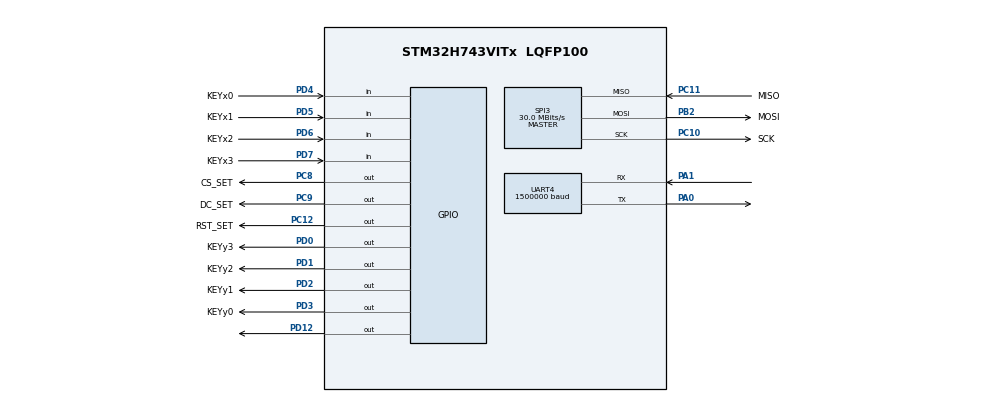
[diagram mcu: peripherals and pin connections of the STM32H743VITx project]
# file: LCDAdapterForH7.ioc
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Dma.Request0=UART4_RX
Dma.UART4_RX.0.Direction=DMA_PERIPH_TO_MEMORY
Dma.UART4_RX.0.EventEnable=DISABLE
Dma.UART4_RX.0.FIFOMode=DMA_FIFOMODE_DISABLE
Dma.UART4_RX.0.Instance=DMA1_Stream0
Dma.UART4_RX.0.MemDataAlignment=DMA_MDATAALIGN_WORD
Dma.UART4_RX.0.MemInc=DMA_MINC_ENABLE
Dma.UART4_RX.0.Mode=DMA_NORMAL
Dma.UART4_RX.0.PeriphDataAlignment=DMA_PDATAALIGN_WORD
Dma.UART4_RX.0.PeriphInc=DMA_PINC_DISABLE
Dma.UART4_RX.0.Polarity=HAL_DMAMUX_REQ_GEN_RISING
Dma.UART4_RX.0.Priority=DMA_PRIORITY_LOW
Dma.UART4_RX.0.RequestNumber=1
Dma.UART4_RX.0.SignalID=NONE
Dma.UART4_RX.0.SyncEnable=DISABLE
Dma.UART4_RX.0.SyncPolarity=HAL_DMAMUX_SYNC_NO_EVENT
Dma.UART4_RX.0.SyncRequestNumber=1
Dma.UART4_RX.0.SyncSignalID=NONE
Mcu.Family=STM32H7
Mcu.Name=STM32H743VITx
Mcu.Package=LQFP100
NVIC.DMA1_Stream0_IRQn=true\:0\:0\:false\:false\:true\:false\:true
NVIC.PriorityGroup=NVIC_PRIORITYGROUP_4
PA0.Mode=Asynchronous
PA0.Signal=UART4_TX
PA1.Mode=Asynchronous
PA1.Signal=UART4_RX
PA13\ (JTMS/SWDIO).Mode=JTAG_4_pins
PA13\ (JTMS/SWDIO).Signal=DEBUG_JTMS-SWDIO
PA14\ (JTCK/SWCLK).Mode=JTAG_4_pins
PA14\ (JTCK/SWCLK).Signal=DEBUG_JTCK-SWCLK
PA15\ (JTDI).Mode=JTAG_4_pins
PA15\ (JTDI).Signal=DEBUG_JTDI
PB2.GPIO_Label=MOSI
PB2.GPIO_Speed=GPIO_SPEED_FREQ_VERY_HIGH
PB2.Mode=Full_Duplex_Master
PB2.Signal=SPI3_MOSI
PB3\ (JTDO/TRACESWO).Mode=JTAG_4_pins
PB3\ (JTDO/TRACESWO).Signal=DEBUG_JTDO-SWO
PC10.GPIO_Label=SCK
PC10.GPIO_Speed=GPIO_SPEED_FREQ_VERY_HIGH
PC10.Mode=Full_Duplex_Master
PC10.Signal=SPI3_SCK
PC11.GPIO_Label=MISO
PC11.GPIO_Speed=GPIO_SPEED_FREQ_VERY_HIGH
PC11.Mode=Full_Duplex_Master
PC11.Signal=SPI3_MISO
PC12.GPIO_Label=RST_SET
PC12.GPIO_Speed=GPIO_SPEED_FREQ_VERY_HIGH
PC12.Signal=GPIO_Output
PC14-OSC32_IN\ (OSC32_IN).Mode=LSE-External-Oscillator
PC14-OSC32_IN\ (OSC32_IN).Signal=RCC_OSC32_IN
PC15-OSC32_OUT\ (OSC32_OUT).Mode=LSE-External-Oscillator
PC15-OSC32_OUT\ (OSC32_OUT).Signal=RCC_OSC32_OUT
PC8.GPIO_Label=CS_SET
PC8.GPIO_Speed=GPIO_SPEED_FREQ_VERY_HIGH
PC8.Signal=GPIO_Output
PC9.GPIO_Label=DC_SET
PC9.GPIO_Speed=GPIO_SPEED_FREQ_LOW
PC9.Signal=GPIO_Output
PD0.GPIO_Label=KEYy3
PD0.Signal=GPIO_Output
PD1.GPIO_Label=KEYy2
PD1.Signal=GPIO_Output
PD12.PinState=GPIO_PIN_SET
PD12.Signal=GPIO_Output
PD2.GPIO_Label=KEYy1
PD2.Signal=GPIO_Output
PD3.GPIO_Label=KEYy0
PD3.Signal=GPIO_Output
PD4.GPIO_Label=KEYx0
PD4.GPIO_PuPd=GPIO_PULLUP
PD4.Signal=GPIO_Input
PD5.GPIO_Label=KEYx1
PD5.GPIO_PuPd=GPIO_PULLUP
PD5.Signal=GPIO_Input
PD6.GPIO_Label=KEYx2
PD6.GPIO_PuPd=GPIO_PULLUP
PD6.Signal=GPIO_Input
PD7.GPIO_Label=KEYx3
PD7.GPIO_PuPd=GPIO_PULLUP
PD7.Signal=GPIO_Input
PH0-OSC_IN\ (PH0).Mode=HSE-External-Clock-Source
PH0-OSC_IN\ (PH0).Signal=RCC_OSC_IN
PH1-OSC_OUT\ (PH1).Mode=HSE-External-Clock-Source
PH1-OSC_OUT\ (PH1).Signal=RCC_OSC_OUT
ProjectManager.HeapSize=0x200
ProjectManager.StackSize=0x400
ProjectManager.TargetToolchain=STM32CubeIDE
RCC.ADCFreq_Value=129000000
RCC.APB1Freq_Value=120000000
RCC.APB2Freq_Value=120000000
RCC.APB3Freq_Value=120000000
RCC.APB4Freq_Value=120000000
RCC.CortexFreq_Value=480000000
RCC.D1PPRE=RCC_APB3_DIV2
RCC.D2PPRE1=RCC_APB1_DIV2
RCC.D2PPRE2=RCC_APB2_DIV2
RCC.D3PPRE=RCC_APB4_DIV2
RCC.DIVM1=4
RCC.DIVN1=60
RCC.HCLKFreq_Value=240000000
RCC.HPRE=RCC_HCLK_DIV2
RCC.PLL2FRACN=0
RCC.PLL3FRACN=0
RCC.PLLFRACN=0
RCC.SYSCLKFreq_VALUE=480000000
RCC.SYSCLKSource=RCC_SYSCLKSOURCE_PLLCLK
RCC.USBFreq_Value=480000000
SPI3.BaudRatePrescaler=SPI_BAUDRATEPRESCALER_16
SPI3.CLKPhase=SPI_PHASE_2EDGE
SPI3.CLKPolarity=SPI_POLARITY_HIGH
SPI3.CalculateBaudRate=30.0 MBits/s
SPI3.DataSize=SPI_DATASIZE_8BIT
SPI3.Direction=SPI_DIRECTION_2LINES
SPI3.Mode=SPI_MODE_MASTER
SPI3.NSSPMode=SPI_NSS_PULSE_DISABLE
SPI3.VirtualType=VM_MASTER
UART4.BaudRate=1500000
board=custom

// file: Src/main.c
/* USER CODE BEGIN Header */
/**
  ******************************************************************************
  * @file           : main.c
  * @brief          : Main program body
  ******************************************************************************
  * @attention
  *
  * <h2><center>&copy; Copyright (c) 2019 STMicroelectronics.
  * All rights reserved.</center></h2>
  *
  * This software component is licensed by ST under BSD 3-Clause license,
  * the "License"; You may not use this file except in compliance with the
  * License. You may obtain a copy of the License at:
  *                        opensource.org/licenses/BSD-3-Clause
  *
  ******************************************************************************
  */
/* USER CODE END Header */

#include <gui.h>
#include "main.h"
#include "dma.h"
#include "spi.h"
#include "usart.h"
#include "gpio.h"

/* USER CODE BEGIN Includes */
#include "KeyPad.h"
#include "MyMain.h"
/* USER CODE END Includes */

/* USER CODE BEGIN PV */
extern uint32_t ImgIn[38400];
/* USER CODE END PV */

void SystemClock_Config(void);

int main(void)
{

  /* MCU Configuration--------------------------------------------------------*/

  /* Reset of all peripherals, Initializes the Flash interface and the Systick. */
  HAL_Init();

  /* Configure the system clock */
  SystemClock_Config();

  /* Initialize all configured peripherals */
  MX_GPIO_Init();
  MX_DMA_Init();
  MX_SPI3_Init();
  MX_UART4_Init();
  /* USER CODE BEGIN 2 */
	Lcd_Init();
	HAL_UART_Receive_DMA(&huart4,ImgIn,38400);
	Lcd_Clear(RED);
  /* USER CODE END 2 */

  /* Infinite loop */
  /* USER CODE BEGIN WHILE */
  while (1)
  {
	  MyMain();
	  //Gui_DrawLine(0,0,100,100,WHITE);
    /* USER CODE END WHILE */

  }
}

void SystemClock_Config(void)
{
  RCC_OscInitTypeDef RCC_OscInitStruct = {0};
  RCC_ClkInitTypeDef RCC_ClkInitStruct = {0};
  RCC_PeriphCLKInitTypeDef PeriphClkInitStruct = {0};

  /** Supply configuration update enable
  */
  HAL_PWREx_ConfigSupply(PWR_LDO_SUPPLY);
  /** Configure the main internal regulator output voltage
  */
  __HAL_PWR_VOLTAGESCALING_CONFIG(PWR_REGULATOR_VOLTAGE_SCALE0);

  while(!__HAL_PWR_GET_FLAG(PWR_FLAG_VOSRDY)) {}
  /** Initializes the CPU, AHB and APB busses clocks
  */
  RCC_OscInitStruct.OscillatorType = RCC_OSCILLATORTYPE_HSI;
  RCC_OscInitStruct.HSIState = RCC_HSI_DIV1;
  RCC_OscInitStruct.HSICalibrationValue = RCC_HSICALIBRATION_DEFAULT;
  RCC_OscInitStruct.PLL.PLLState = RCC_PLL_ON;
  RCC_OscInitStruct.PLL.PLLSource = RCC_PLLSOURCE_HSI;
  RCC_OscInitStruct.PLL.PLLM = 4;
  RCC_OscInitStruct.PLL.PLLN = 60;
  RCC_OscInitStruct.PLL.PLLP = 2;
  RCC_OscInitStruct.PLL.PLLQ = 2;
  RCC_OscInitStruct.PLL.PLLR = 2;
  RCC_OscInitStruct.PLL.PLLRGE = RCC_PLL1VCIRANGE_3;
  RCC_OscInitStruct.PLL.PLLVCOSEL = RCC_PLL1VCOWIDE;
  RCC_OscInitStruct.PLL.PLLFRACN = 0;
  if (HAL_RCC_OscConfig(&RCC_OscInitStruct) != HAL_OK)
  {
    Error_Handler();
  }
  /** Initializes the CPU, AHB and APB busses clocks
  */
  RCC_ClkInitStruct.ClockType = RCC_CLOCKTYPE_HCLK|RCC_CLOCKTYPE_SYSCLK
                              |RCC_CLOCKTYPE_PCLK1|RCC_CLOCKTYPE_PCLK2
                              |RCC_CLOCKTYPE_D3PCLK1|RCC_CLOCKTYPE_D1PCLK1;
  RCC_ClkInitStruct.SYSCLKSource = RCC_SYSCLKSOURCE_PLLCLK;
  RCC_ClkInitStruct.SYSCLKDivider = RCC_SYSCLK_DIV1;
  RCC_ClkInitStruct.AHBCLKDivider = RCC_HCLK_DIV2;
  RCC_ClkInitStruct.APB3CLKDivider = RCC_APB3_DIV2;
  RCC_ClkInitStruct.APB1CLKDivider = RCC_APB1_DIV2;
  RCC_ClkInitStruct.APB2CLKDivider = RCC_APB2_DIV2;
  RCC_ClkInitStruct.APB4CLKDivider = RCC_APB4_DIV2;

  if (HAL_RCC_ClockConfig(&RCC_ClkInitStruct, FLASH_LATENCY_4) != HAL_OK)
  {
    Error_Handler();
  }
  PeriphClkInitStruct.PeriphClockSelection = RCC_PERIPHCLK_UART4|RCC_PERIPHCLK_SPI3;
  PeriphClkInitStruct.Spi123ClockSelection = RCC_SPI123CLKSOURCE_PLL;
  PeriphClkInitStruct.Usart234578ClockSelection = RCC_USART234578CLKSOURCE_D2PCLK1;
  if (HAL_RCCEx_PeriphCLKConfig(&PeriphClkInitStruct) != HAL_OK)
  {
    Error_Handler();
  }
}

void Error_Handler(void)
{
}

/************************ (C) COPYRIGHT STMicroelectronics *****END OF FILE****/
